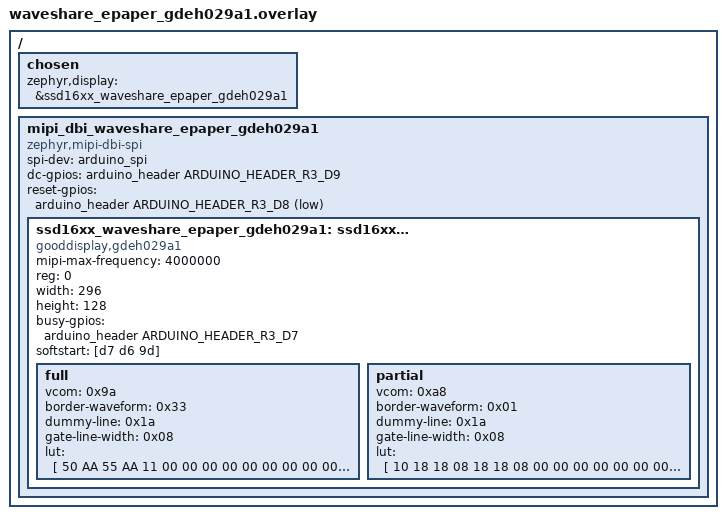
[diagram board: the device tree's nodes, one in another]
/*
 * Copyright (c) 2019, PHYTEC Messtechnik GmbH
 *
 * SPDX-License-Identifier: Apache-2.0
 */

#include "waveshare_epaper_common.dtsi"
#include <zephyr/dt-bindings/gpio/arduino-header-r3.h>

/ {
	chosen {
		zephyr,display = &ssd16xx_waveshare_epaper_gdeh029a1;
	};

	mipi_dbi_waveshare_epaper_gdeh029a1 {
		compatible = "zephyr,mipi-dbi-spi";
		spi-dev = <&arduino_spi>;
		dc-gpios = <&arduino_header ARDUINO_HEADER_R3_D9 GPIO_ACTIVE_HIGH>;
		reset-gpios = <&arduino_header ARDUINO_HEADER_R3_D8 GPIO_ACTIVE_LOW>;
		#address-cells = <1>;
		#size-cells = <0>;

		ssd16xx_waveshare_epaper_gdeh029a1: ssd16xxfb@0 {
			compatible = "gooddisplay,gdeh029a1", "solomon,ssd1608";
			mipi-max-frequency = <4000000>;
			reg = <0>;
			width = <296>;
			height = <128>;
			busy-gpios = <&arduino_header ARDUINO_HEADER_R3_D7 GPIO_ACTIVE_HIGH>;

			softstart = [d7 d6 9d];

			full {
				vcom = <0x9a>;
				border-waveform = <0x33>;
				dummy-line = <0x1a>;
				gate-line-width = <0x08>;
				lut = [
					50 AA 55 AA 11 00 00 00
					00 00 00 00 00 00 00 00
					00 00 00 00 FF FF 1F 00
					00 00 00 00 00 00
				];
			};

			partial {
				vcom = <0xa8>;
				border-waveform = <0x01>;
				dummy-line = <0x1a>;
				gate-line-width = <0x08>;
				lut = [
					10 18 18 08 18 18 08 00
					00 00 00 00 00 00 00 00
					00 00 00 00 13 14 44 12
					00 00 00 00 00 00
				];
			};
		};
	};
};
